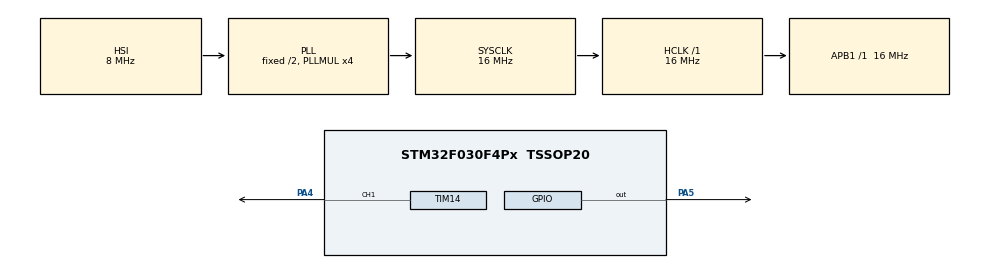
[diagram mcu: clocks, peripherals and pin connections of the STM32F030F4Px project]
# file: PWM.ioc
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Mcu.Family=STM32F0
Mcu.Name=STM32F030F4Px
Mcu.Package=TSSOP20
PA4.GPIO_Speed=GPIO_SPEED_FREQ_HIGH
PA4.Signal=S_TIM14_CH1
PA5.Signal=GPIO_Output
PF0-OSC_IN.Mode=HSE-External-Oscillator
PF0-OSC_IN.Signal=RCC_OSC_IN
PF1-OSC_OUT.Mode=HSE-External-Oscillator
PF1-OSC_OUT.Signal=RCC_OSC_OUT
ProjectManager.HeapSize=0x200
ProjectManager.StackSize=0x400
ProjectManager.TargetToolchain=MDK-ARM V5
RCC.AHBFreq_Value=16000000
RCC.APB1Freq_Value=16000000
RCC.APB1TimFreq_Value=16000000
RCC.HCLKFreq_Value=16000000
RCC.PLLMUL=RCC_PLL_MUL4
RCC.SYSCLKFreq_VALUE=16000000
RCC.SYSCLKSource=RCC_SYSCLKSOURCE_PLLCLK
SH.S_TIM14_CH1.0=TIM14_CH1,PWM Generation1 CH1
TIM14.Channel=TIM_CHANNEL_1
TIM14.Period=15999
TIM14.Prescaler=999
TIM14.Pulse=7999
VP_TIM14_VS_ClockSourceINT.Mode=Enable_Timer
board=PWM

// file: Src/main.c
/**
  ******************************************************************************
  * File Name          : main.c
  * Description        : Main program body
  ******************************************************************************
  ** This notice applies to any and all portions of this file
  * that are not between comment pairs USER CODE BEGIN and
  * USER CODE END. Other portions of this file, whether
  * inserted by the user or by software development tools
  * are owned by their respective copyright owners.
  *
  * COPYRIGHT(c) 2020 STMicroelectronics
  *
  * Redistribution and use in source and binary forms, with or without modification,
  * are permitted provided that the following conditions are met:
  *   1. Redistributions of source code must retain the above copyright notice,
  *      this list of conditions and the following disclaimer.
  *   2. Redistributions in binary form must reproduce the above copyright notice,
  *      this list of conditions and the following disclaimer in the documentation
  *      and/or other materials provided with the distribution.
  *   3. Neither the name of STMicroelectronics nor the names of its contributors
  *      may be used to endorse or promote products derived from this software
  *      without specific prior written permission.
  *
  * THIS SOFTWARE IS PROVIDED BY THE COPYRIGHT HOLDERS AND CONTRIBUTORS "AS IS"
  * AND ANY EXPRESS OR IMPLIED WARRANTIES, INCLUDING, BUT NOT LIMITED TO, THE
  * IMPLIED WARRANTIES OF MERCHANTABILITY AND FITNESS FOR A PARTICULAR PURPOSE ARE
  * DISCLAIMED. IN NO EVENT SHALL THE COPYRIGHT HOLDER OR CONTRIBUTORS BE LIABLE
  * FOR ANY DIRECT, INDIRECT, INCIDENTAL, SPECIAL, EXEMPLARY, OR CONSEQUENTIAL
  * DAMAGES (INCLUDING, BUT NOT LIMITED TO, PROCUREMENT OF SUBSTITUTE GOODS OR
  * SERVICES; LOSS OF USE, DATA, OR PROFITS; OR BUSINESS INTERRUPTION) HOWEVER
  * CAUSED AND ON ANY THEORY OF LIABILITY, WHETHER IN CONTRACT, STRICT LIABILITY,
  * OR TORT (INCLUDING NEGLIGENCE OR OTHERWISE) ARISING IN ANY WAY OUT OF THE USE
  * OF THIS SOFTWARE, EVEN IF ADVISED OF THE POSSIBILITY OF SUCH DAMAGE.
  *
  ******************************************************************************
  */

#include "main.h"
#include "stm32f0xx_hal.h"

TIM_HandleTypeDef htim14;

/* USER CODE BEGIN PV */
/* Private variables ---------------------------------------------------------*/

/* USER CODE END PV */

void SystemClock_Config(void);
static void MX_GPIO_Init(void);
static void MX_TIM14_Init(void);
void HAL_TIM_MspPostInit(TIM_HandleTypeDef *htim);

/* USER CODE BEGIN PFP */
/* Private function prototypes -----------------------------------------------*/

/* USER CODE END PFP */

int main(void)
{

  /* MCU Configuration----------------------------------------------------------*/

  /* Reset of all peripherals, Initializes the Flash interface and the Systick. */
  HAL_Init();

  /* Configure the system clock */
  SystemClock_Config();

  /* Initialize all configured peripherals */
  MX_GPIO_Init();
  MX_TIM14_Init();

  /* USER CODE BEGIN 2 */
	HAL_TIM_PWM_Start(&htim14, TIM_CHANNEL_1);
  /* USER CODE END 2 */

  /* Infinite loop */
  while (1)
  {

  }

}

/** System Clock Configuration
*/
void SystemClock_Config(void)
{

  RCC_OscInitTypeDef RCC_OscInitStruct;
  RCC_ClkInitTypeDef RCC_ClkInitStruct;

    /**Initializes the CPU, AHB and APB busses clocks
    */
  RCC_OscInitStruct.OscillatorType = RCC_OSCILLATORTYPE_HSI;
  RCC_OscInitStruct.HSIState = RCC_HSI_ON;
  RCC_OscInitStruct.HSICalibrationValue = 16;
  RCC_OscInitStruct.PLL.PLLState = RCC_PLL_ON;
  RCC_OscInitStruct.PLL.PLLSource = RCC_PLLSOURCE_HSI;
  RCC_OscInitStruct.PLL.PLLMUL = RCC_PLL_MUL4;
  RCC_OscInitStruct.PLL.PREDIV = RCC_PREDIV_DIV1;
  if (HAL_RCC_OscConfig(&RCC_OscInitStruct) != HAL_OK)
  {
    _Error_Handler(__FILE__, __LINE__);
  }

    /**Initializes the CPU, AHB and APB busses clocks
    */
  RCC_ClkInitStruct.ClockType = RCC_CLOCKTYPE_HCLK|RCC_CLOCKTYPE_SYSCLK
                              |RCC_CLOCKTYPE_PCLK1;
  RCC_ClkInitStruct.SYSCLKSource = RCC_SYSCLKSOURCE_PLLCLK;
  RCC_ClkInitStruct.AHBCLKDivider = RCC_SYSCLK_DIV1;
  RCC_ClkInitStruct.APB1CLKDivider = RCC_HCLK_DIV1;

  if (HAL_RCC_ClockConfig(&RCC_ClkInitStruct, FLASH_LATENCY_0) != HAL_OK)
  {
    _Error_Handler(__FILE__, __LINE__);
  }

    /**Configure the Systick interrupt time
    */
  HAL_SYSTICK_Config(HAL_RCC_GetHCLKFreq()/1000);

    /**Configure the Systick
    */
  HAL_SYSTICK_CLKSourceConfig(SYSTICK_CLKSOURCE_HCLK);

  /* SysTick_IRQn interrupt configuration */
  HAL_NVIC_SetPriority(SysTick_IRQn, 0, 0);
}

/* TIM14 init function */
static void MX_TIM14_Init(void)
{

  TIM_OC_InitTypeDef sConfigOC;

  htim14.Instance = TIM14;
  htim14.Init.Prescaler = 1;
  htim14.Init.CounterMode = TIM_COUNTERMODE_UP;
  htim14.Init.Period = 4;
  htim14.Init.ClockDivision = TIM_CLOCKDIVISION_DIV1;
  htim14.Init.AutoReloadPreload = TIM_AUTORELOAD_PRELOAD_DISABLE;
  if (HAL_TIM_Base_Init(&htim14) != HAL_OK)
  {
    _Error_Handler(__FILE__, __LINE__);
  }

  if (HAL_TIM_PWM_Init(&htim14) != HAL_OK)
  {
    _Error_Handler(__FILE__, __LINE__);
  }

  sConfigOC.OCMode = TIM_OCMODE_PWM1;
  sConfigOC.Pulse = 2;
  sConfigOC.OCPolarity = TIM_OCPOLARITY_HIGH;
  sConfigOC.OCFastMode = TIM_OCFAST_DISABLE;
  if (HAL_TIM_PWM_ConfigChannel(&htim14, &sConfigOC, TIM_CHANNEL_1) != HAL_OK)
  {
    _Error_Handler(__FILE__, __LINE__);
  }

  HAL_TIM_MspPostInit(&htim14);

}

/** Configure pins as
        * Analog
        * Input
        * Output
        * EVENT_OUT
        * EXTI
*/
static void MX_GPIO_Init(void)
{

  GPIO_InitTypeDef GPIO_InitStruct;

  /* GPIO Ports Clock Enable */
  __HAL_RCC_GPIOF_CLK_ENABLE();
  __HAL_RCC_GPIOA_CLK_ENABLE();

  /*Configure GPIO pin Output Level */
  HAL_GPIO_WritePin(GPIOA, GPIO_PIN_5, GPIO_PIN_RESET);

  /*Configure GPIO pin : PA5 */
  GPIO_InitStruct.Pin = GPIO_PIN_5;
  GPIO_InitStruct.Mode = GPIO_MODE_OUTPUT_PP;
  GPIO_InitStruct.Pull = GPIO_NOPULL;
  GPIO_InitStruct.Speed = GPIO_SPEED_FREQ_LOW;
  HAL_GPIO_Init(GPIOA, &GPIO_InitStruct);

}

void _Error_Handler(char * file, int line)
{
  while(1)
  {
  }
}

/************************ (C) COPYRIGHT STMicroelectronics *****END OF FILE****/
